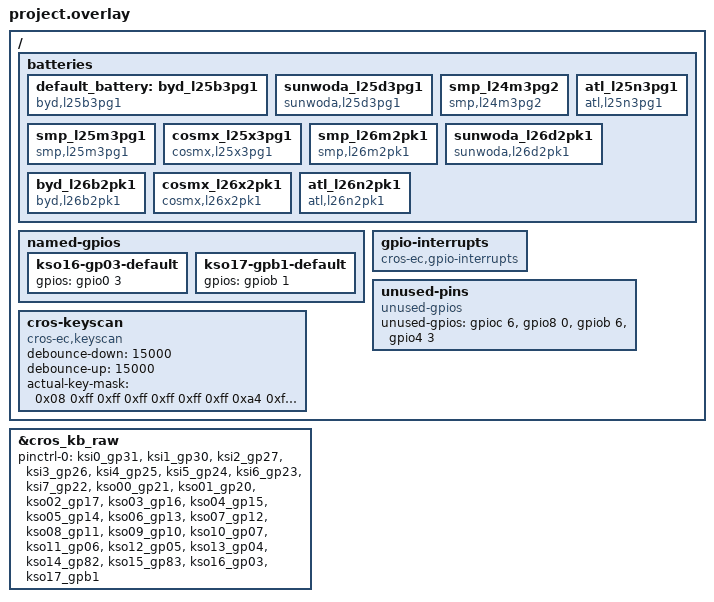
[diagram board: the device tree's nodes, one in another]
/* Copyright 2026 The ChromiumOS Authors
 * Use of this source code is governed by a BSD-style license that can be
 * found in the LICENSE file.
 */

#include <cros/cbi_flash.dtsi>
#include "../npcx_generated.dtsi"
#include "../interrupts.dtsi"
#include "../npcx_common.dtsi"
#include "../npcx_default_gpio_pinctrl.dtsi"
#include "../npcx_keyboard.dtsi"
#include "../npcx_overlay.dtsi"
#include "../npcx_usbc.dtsi"
#include "../power_signal.dtsi"
#include "../usba.dtsi"
#include "led_pins.dtsi"
#include "led_policy.dtsi"
#include "motionsense.dtsi"
#include "cbi.dtsi"

/ {
	batteries {
		default_battery: byd_l25b3pg1 {
			compatible = "byd,l25b3pg1", "battery-smart";
		};
		sunwoda_l25d3pg1 {
			compatible = "sunwoda,l25d3pg1", "battery-smart";
		};
		smp_l24m3pg2 {
			compatible = "smp,l24m3pg2", "battery-smart";
		};
		smp_l25m3pg1 {
			compatible = "smp,l25m3pg1", "battery-smart";
		};
		atl_l25n3pg1 {
			compatible = "atl,l25n3pg1", "battery-smart";
		};
		cosmx_l25x3pg1 {
			compatible = "cosmx,l25x3pg1", "battery-smart";
		};
		smp_l26m2pk1 {
			compatible = "smp,l26m2pk1", "battery-smart";
		};
		sunwoda_l26d2pk1 {
			compatible = "sunwoda,l26d2pk1", "battery-smart";
		};
		byd_l26b2pk1 {
			compatible = "byd,l26b2pk1", "battery-smart";
		};
		cosmx_l26x2pk1 {
			compatible = "cosmx,l26x2pk1", "battery-smart";
		};
		atl_l26n2pk1 {
			compatible = "atl,l26n2pk1", "battery-smart";
		};
	};

	named-gpios {
		/delete-node/ en_usb_c0_dev_mode;
		/delete-node/ usb_c0_dp_hpd;
		/delete-node/ ec_kso_02_inv;
		kso16-gp03-default {
			gpios = <&gpio0 3 (GPIO_OPEN_DRAIN | GPIO_PULL_UP)>;
		};
		kso17-gpb1-default {
			gpios = <&gpiob 1 (GPIO_OPEN_DRAIN | GPIO_PULL_UP)>;
		};
	};

	gpio-interrupts {
		compatible = "cros-ec,gpio-interrupts";

		/delete-node/ ec-imu;
	};

	unused-pins {
		compatible = "unused-gpios";
		unused-gpios =
		<&gpioc 6 0>,
		<&gpio8 0 0>,
		<&gpiob 6 0>,
		<&gpio4 3 0>;
	};

	cros-keyscan {
		compatible = "cros-ec,keyscan";
		debounce-down = <15000>;
		debounce-up = <15000>;
		actual-key-mask = <
			0x08  /* C0 */
			0xff  /* C1 */
			0xff  /* C2 */
			0xff  /* C3 */
			0xff  /* C4 */
			0xff  /* C5 */
			0xff  /* C6 */
			0xa4  /* C7 */
			0xff  /* C8 */
			0xff  /* C9 */
			0x55  /* C10 */
			0xff  /* C11 */
			0xff  /* C12 */
			0x40  /* C13 */
			0x0a  /* C14 */
			0x40  /* C15 */
			0xff  /* C16 */
			0xff  /* C17 */
		>;
	};
};

&cros_kb_raw {
	pinctrl-0 = <
		&ksi0_gp31
		&ksi1_gp30
		&ksi2_gp27
		&ksi3_gp26
		&ksi4_gp25
		&ksi5_gp24
		&ksi6_gp23
		&ksi7_gp22
		&kso00_gp21
		&kso01_gp20
		&kso02_gp17
		&kso03_gp16
		&kso04_gp15
		&kso05_gp14
		&kso06_gp13
		&kso07_gp12
		&kso08_gp11
		&kso09_gp10
		&kso10_gp07
		&kso11_gp06
		&kso12_gp05
		&kso13_gp04
		&kso14_gp82
		&kso15_gp83
		&kso16_gp03
		&kso17_gpb1
	>;
};
